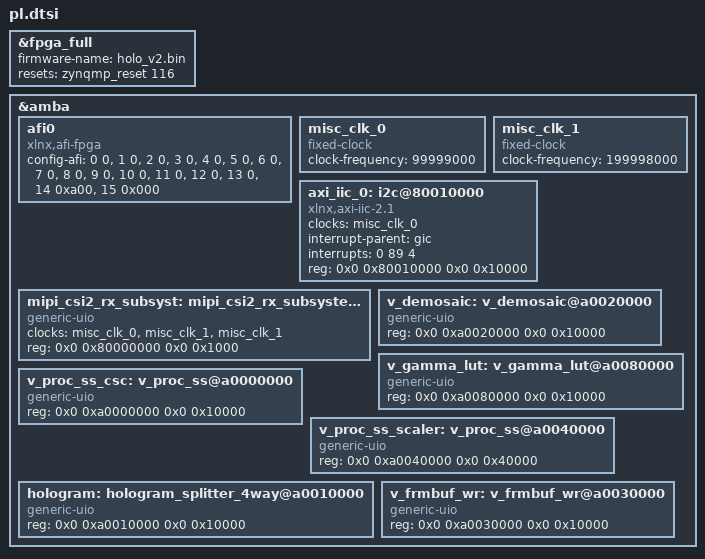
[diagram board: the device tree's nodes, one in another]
/dts-v1/;
/plugin/;
/ {
	fragment@0 {
		target = <&fpga_full>;
		overlay0: __overlay__ {
			#address-cells = <2>;
			#size-cells = <2>;
			firmware-name = "holo_v2.bin";
			resets = <&zynqmp_reset 116>;
		};
	};
	fragment@1 {
		target = <&amba>;
		overlay1: __overlay__ {
			afi0: afi0 {
				compatible = "xlnx,afi-fpga";
				config-afi = < 0 0>, <1 0>, <2 0>, <3 0>, <4 0>, <5 0>, <6 0>, <7 0>, <8 0>, <9 0>, <10 0>, <11 0>, <12 0>, <13 0>, <14 0xa00>, <15 0x000>;
			};
		};
	};
	fragment@2 {
		target = <&amba>;
		overlay2: __overlay__ {
			#address-cells = <2>;
			#size-cells = <2>;

			misc_clk_0: misc_clk_0 {
				#clock-cells = <0>;
				clock-frequency = <99999000>;
				compatible = "fixed-clock";
			};

			misc_clk_1: misc_clk_1 {
				#clock-cells = <0>;
				clock-frequency = <199998000>;
				compatible = "fixed-clock";
			};

			/* IMX219 I2C */
			axi_iic_0: i2c@80010000 {
				#address-cells = <1>;
				#size-cells = <0>;
				clock-names = "s_axi_aclk";
				clocks = <&misc_clk_0>;
				compatible = "xlnx,axi-iic-2.1", "xlnx,xps-iic-2.00.a";
				interrupt-names = "iic2intc_irpt";
				interrupt-parent = <&gic>;
				interrupts = <0 89 4>;
				reg = <0x0 0x80010000 0x0 0x10000>;
			};

			/* MIPI CSI-2 RX */
			mipi_csi2_rx_subsyst: mipi_csi2_rx_subsystem@80000000 {
				clock-names = "lite_aclk", "dphy_clk_200M", "video_aclk";
				clocks = <&misc_clk_0>, <&misc_clk_1>, <&misc_clk_1>;
				compatible = "generic-uio";
				reg = <0x0 0x80000000 0x0 0x1000>;
			};

			/* Demosaic */
			v_demosaic: v_demosaic@a0020000 {
				compatible = "generic-uio";
				reg = <0x0 0xa0020000 0x0 0x10000>;
			};

			/* Gamma LUT */
			v_gamma_lut: v_gamma_lut@a0080000 {
				compatible = "generic-uio";
				reg = <0x0 0xa0080000 0x0 0x10000>;
			};

			/* VPSS CSC */
			v_proc_ss_csc: v_proc_ss@a0000000 {
				compatible = "generic-uio";
				reg = <0x0 0xa0000000 0x0 0x10000>;
			};

			/* VPSS Scaler */
			v_proc_ss_scaler: v_proc_ss@a0040000 {
				compatible = "generic-uio";
				reg = <0x0 0xa0040000 0x0 0x40000>;
			};

			/* Hologram Splitter */
			hologram: hologram_splitter_4way@a0010000 {
				compatible = "generic-uio";
				reg = <0x0 0xa0010000 0x0 0x10000>;
			};

			/* FrameBuffer Write DMA */
			v_frmbuf_wr: v_frmbuf_wr@a0030000 {
				compatible = "generic-uio";
				reg = <0x0 0xa0030000 0x0 0x10000>;
			};
		};
	};
};
